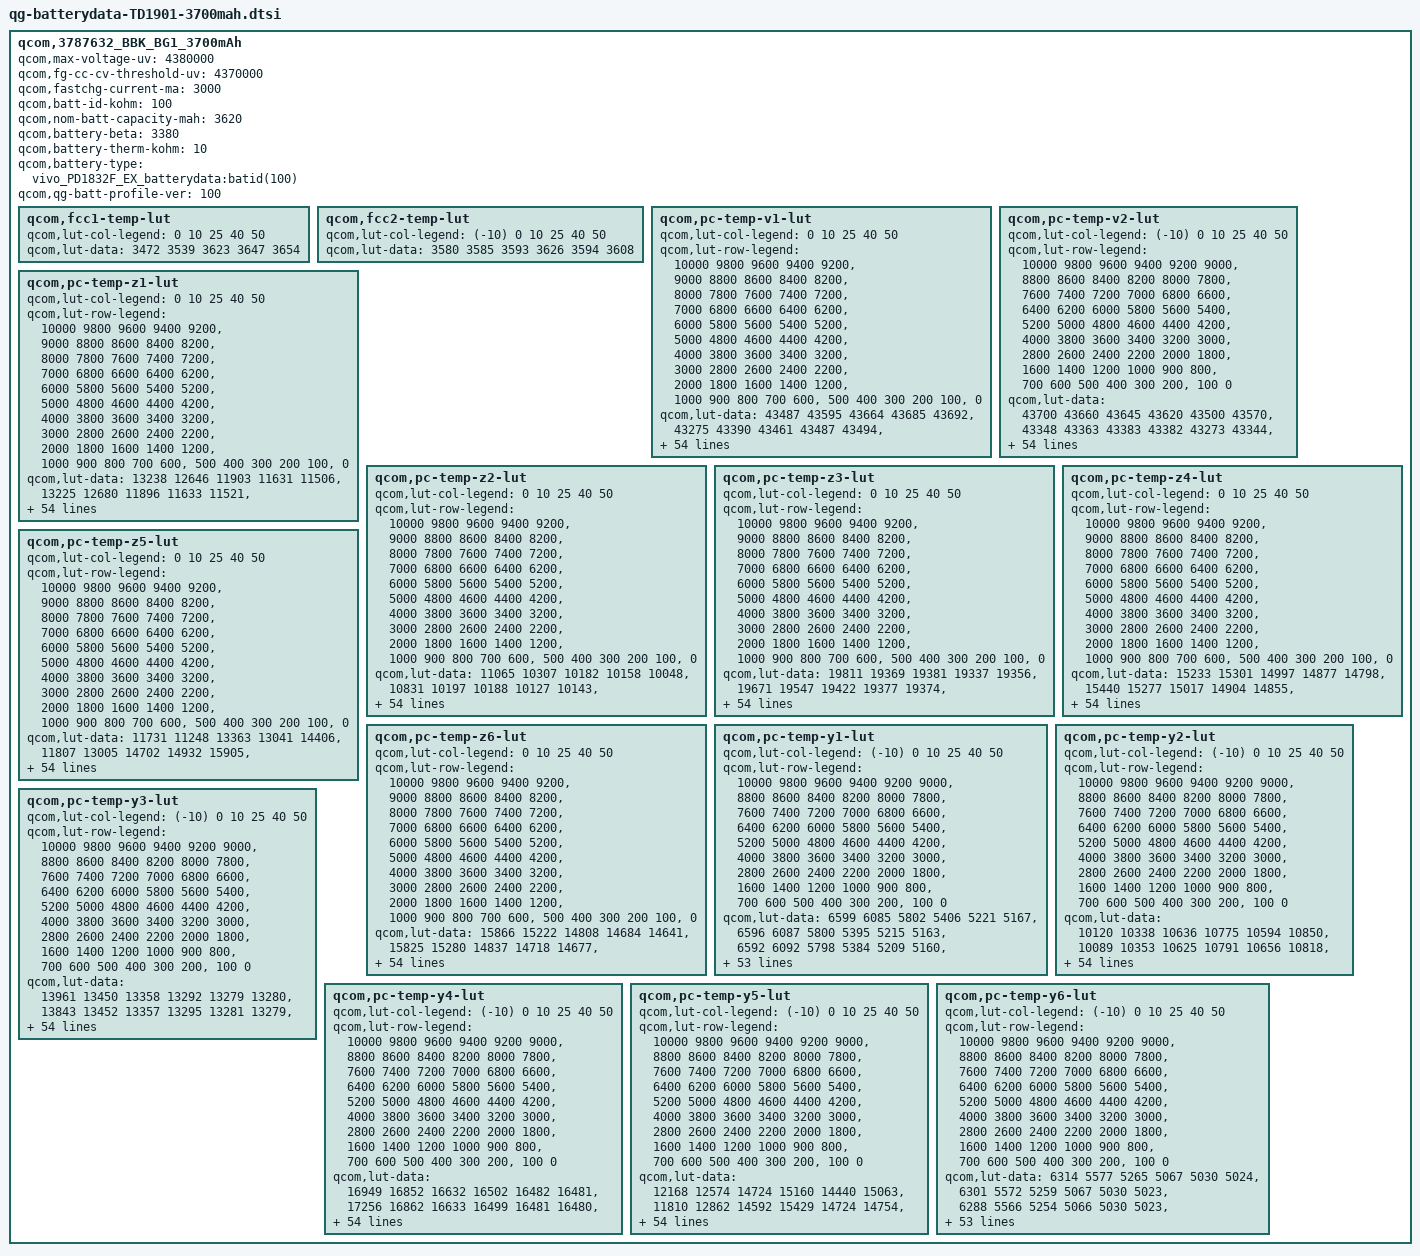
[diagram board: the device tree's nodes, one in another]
/*
 * Copyright (c) 2018, The Linux Foundation. All rights reserved.
 *
 * This program is free software; you can redistribute it and/or modify
 * it under the terms of the GNU General Public License version 2 and
 * only version 2 as published by the Free Software Foundation.
 *
 * This program is distributed in the hope that it will be useful,
 * but WITHOUT ANY WARRANTY; without even the implied warranty of
 * MERCHANTABILITY or FITNESS FOR A PARTICULAR PURPOSE.  See the
 * GNU General Public License for more details.
 */

qcom,3787632_BBK_BG1_3700mAh {
    /* 3787632_BBK_BG1_3700mAh_averaged_MasterSlave_Dec7th2018 */
    qcom,max-voltage-uv = <4380000>;
    qcom,fg-cc-cv-threshold-uv = <4370000>;
    qcom,fastchg-current-ma = <3000>;
    qcom,batt-id-kohm = <100>;
    qcom,nom-batt-capacity-mah = <3620>;/*min value*/
    qcom,battery-beta = <3380>;
    qcom,battery-therm-kohm = <10>;
    qcom,battery-type = "vivo_PD1832F_EX_batterydata:batid(100)";
    qcom,qg-batt-profile-ver = <100>;

	qcom,fcc1-temp-lut {
		qcom,lut-col-legend = <0 10 25 40 50>;
		qcom,lut-data = <3472 3539 3623 3647 3654>;
	};

	qcom,fcc2-temp-lut {
		qcom,lut-col-legend = <(-10) 0 10 25 40 50>;
		qcom,lut-data = <3580 3585 3593 3626 3594 3608>;
	};

	qcom,pc-temp-v1-lut {
		qcom,lut-col-legend = <0 10 25 40 50>;
		qcom,lut-row-legend = <10000 9800 9600 9400 9200>,
			<9000 8800 8600 8400 8200>,
			<8000 7800 7600 7400 7200>,
			<7000 6800 6600 6400 6200>,
			<6000 5800 5600 5400 5200>,
			<5000 4800 4600 4400 4200>,
			<4000 3800 3600 3400 3200>,
			<3000 2800 2600 2400 2200>,
			<2000 1800 1600 1400 1200>,
			<1000 900 800 700 600>,
			<500 400 300 200 100>,
			<0>;
		qcom,lut-data = <43487 43595 43664 43685 43692>,
			<43275 43390 43461 43487 43494>,
			<43054 43179 43248 43279 43290>,
			<42821 42960 43026 43060 43081>,
			<42580 42724 42800 42835 42865>,
			<42353 42481 42573 42611 42643>,
			<42140 42255 42344 42384 42415>,
			<41935 42044 42118 42160 42188>,
			<41729 41838 41895 41935 41963>,
			<41519 41627 41675 41713 41740>,
			<41323 41416 41460 41494 41521>,
			<41157 41218 41250 41278 41305>,
			<41005 41047 41047 41070 41094>,
			<40820 40877 40853 40875 40893>,
			<40568 40669 40660 40685 40699>,
			<40311 40422 40457 40490 40507>,
			<40124 40197 40248 40287 40316>,
			<39980 40033 40063 40098 40134>,
			<39826 39888 39917 39940 39968>,
			<39614 39710 39773 39790 39809>,
			<39382 39471 39577 39605 39622>,
			<39203 39243 39328 39367 39388>,
			<39073 39084 39114 39146 39167>,
			<38962 38955 38959 38983 39000>,
			<38860 38842 38828 38845 38859>,
			<38768 38737 38711 38723 38733>,
			<38684 38644 38607 38614 38620>,
			<38608 38559 38513 38515 38517>,
			<38539 38481 38425 38422 38423>,
			<38475 38411 38344 38336 38334>,
			<38417 38348 38275 38259 38253>,
			<38363 38291 38213 38188 38179>,
			<38316 38240 38160 38124 38110>,
			<38273 38196 38112 38068 38048>,
			<38235 38155 38069 38019 37992>,
			<38204 38117 38026 37966 37927>,
			<38173 38083 37985 37910 37850>,
			<38126 38037 37938 37848 37765>,
			<38038 37957 37867 37770 37678>,
			<37926 37849 37767 37674 37587>,
			<37812 37737 37658 37567 37482>,
			<37684 37613 37535 37440 37347>,
			<37534 37472 37398 37302 37206>,
			<37369 37307 37238 37146 37068>,
			<37249 37181 37117 37039 36963>,
			<37211 37123 37053 36975 36919>,
			<37191 37103 37033 36955 36891>,
			<37168 37087 37017 36941 36871>,
			<37126 37051 36985 36903 36822>,
			<36967 36895 36813 36691 36580>,
			<36583 36512 36436 36311 36215>,
			<36102 36035 35959 35836 35751>,
			<35489 35424 35348 35226 35134>,
			<34657 34593 34518 34395 34297>,
			<33341 33291 33222 33100 32998>,
			<30000 30000 30000 30000 30000>;
	};

	qcom,pc-temp-v2-lut {
		qcom,lut-col-legend = <(-10) 0 10 25 40 50>;
		qcom,lut-row-legend = <10000 9800 9600 9400 9200 9000>,
			<8800 8600 8400 8200 8000 7800>,
			<7600 7400 7200 7000 6800 6600>,
			<6400 6200 6000 5800 5600 5400>,
			<5200 5000 4800 4600 4400 4200>,
			<4000 3800 3600 3400 3200 3000>,
			<2800 2600 2400 2200 2000 1800>,
			<1600 1400 1200 1000 900 800>,
			<700 600 500 400 300 200>,
			<100 0>;
		qcom,lut-data = <43700 43660 43645 43620 43500 43570>,
			<43348 43363 43383 43382 43273 43344>,
			<43021 43083 43129 43148 43046 43117>,
			<42723 42820 42884 42915 42819 42891>,
			<42451 42576 42649 42687 42593 42663>,
			<42196 42340 42419 42459 42367 42437>,
			<41949 42108 42190 42230 42141 42211>,
			<41713 41880 41966 42004 41918 41987>,
			<41494 41655 41747 41781 41697 41766>,
			<41290 41427 41533 41560 41479 41548>,
			<41099 41210 41323 41343 41265 41333>,
			<40928 41027 41123 41131 41057 41121>,
			<40777 40866 40931 40923 40854 40912>,
			<40586 40684 40731 40721 40656 40711>,
			<40261 40440 40509 40521 40457 40516>,
			<39892 40174 40286 40326 40266 40327>,
			<39640 39939 40087 40136 40089 40146>,
			<39462 39724 39907 39950 39925 39973>,
			<39289 39519 39720 39763 39754 39795>,
			<39088 39320 39500 39578 39558 39611>,
			<38880 39132 39272 39390 39350 39422>,
			<38694 38959 39077 39188 39149 39220>,
			<38521 38800 38906 38972 38947 38998>,
			<38378 38655 38755 38790 38770 38808>,
			<38285 38527 38625 38656 38638 38671>,
			<38215 38411 38509 38543 38527 38558>,
			<38155 38305 38404 38438 38426 38454>,
			<38102 38203 38307 38340 38331 38358>,
			<38052 38113 38216 38249 38243 38269>,
			<38004 38039 38132 38167 38161 38182>,
			<37958 37977 38054 38091 38085 38100>,
			<37913 37925 37982 38020 38013 38024>,
			<37870 37884 37915 37955 37949 37958>,
			<37827 37848 37854 37890 37885 37889>,
			<37782 37811 37804 37822 37803 37794>,
			<37737 37775 37765 37752 37700 37673>,
			<37686 37733 37720 37678 37597 37559>,
			<37626 37683 37658 37596 37506 37459>,
			<37556 37621 37581 37510 37418 37364>,
			<37477 37540 37494 37426 37327 37270>,
			<37387 37422 37392 37342 37235 37179>,
			<37283 37287 37278 37241 37136 37080>,
			<37163 37151 37140 37098 37005 36955>,
			<37029 37014 37004 36980 36879 36843>,
			<36916 36911 36936 36915 36833 36786>,
			<36820 36831 36890 36876 36805 36747>,
			<36778 36797 36866 36857 36789 36727>,
			<36730 36754 36828 36831 36760 36706>,
			<36651 36660 36731 36748 36642 36627>,
			<36478 36420 36457 36466 36312 36328>,
			<36124 36002 36007 36018 35866 35900>,
			<35617 35450 35442 35457 35299 35383>,
			<34955 34732 34713 34732 34552 34663>,
			<34019 33703 33668 33694 33533 33760>,
			<32552 32246 32385 32504 32347 32353>,
			<29244 29005 29003 29004 29002 29001>;
	};

	qcom,pc-temp-z1-lut {
		qcom,lut-col-legend = <0 10 25 40 50>;
		qcom,lut-row-legend = <10000 9800 9600 9400 9200>,
			<9000 8800 8600 8400 8200>,
			<8000 7800 7600 7400 7200>,
			<7000 6800 6600 6400 6200>,
			<6000 5800 5600 5400 5200>,
			<5000 4800 4600 4400 4200>,
			<4000 3800 3600 3400 3200>,
			<3000 2800 2600 2400 2200>,
			<2000 1800 1600 1400 1200>,
			<1000 900 800 700 600>,
			<500 400 300 200 100>,
			<0>;
		qcom,lut-data = <13238 12646 11903 11631 11506>,
			<13225 12680 11896 11633 11521>,
			<13214 12663 11889 11633 11529>,
			<13202 12647 11879 11628 11530>,
			<13189 12632 11870 11622 11529>,
			<13184 12619 11862 11619 11527>,
			<13184 12608 11854 11616 11528>,
			<13185 12597 11847 11613 11528>,
			<13187 12589 11841 11607 11525>,
			<13197 12589 11836 11602 11520>,
			<13205 12595 11832 11601 11516>,
			<13202 12597 11829 11600 11513>,
			<13193 12587 11826 11600 11511>,
			<13180 12572 11822 11598 11515>,
			<13151 12561 11819 11596 11523>,
			<13124 12547 11818 11595 11524>,
			<13121 12540 11816 11594 11517>,
			<13130 12544 11815 11594 11510>,
			<13141 12553 11815 11594 11512>,
			<13158 12558 11815 11595 11517>,
			<13177 12559 11817 11595 11519>,
			<13182 12558 11819 11598 11523>,
			<13166 12558 11821 11601 11527>,
			<13148 12561 11827 11604 11529>,
			<13146 12564 11834 11607 11533>,
			<13146 12568 11839 11610 11533>,
			<13147 12574 11844 11613 11531>,
			<13163 12575 11848 11616 11530>,
			<13194 12577 11853 11620 11535>,
			<13204 12578 11858 11625 11549>,
			<13192 12580 11863 11629 11555>,
			<13177 12582 11868 11633 11551>,
			<13173 12585 11873 11636 11547>,
			<13172 12587 11877 11639 11550>,
			<13172 12590 11881 11643 11563>,
			<13176 12592 11884 11646 11568>,
			<13181 12594 11891 11651 11569>,
			<13187 12597 11898 11655 11571>,
			<13189 12601 11903 11658 11572>,
			<13188 12606 11908 11661 11572>,
			<13189 12610 11912 11664 11572>,
			<13194 12612 11916 11668 11579>,
			<13197 12616 11919 11671 11582>,
			<13198 12625 11922 11673 11578>,
			<13199 12623 11924 11673 11589>,
			<13196 12620 11925 11673 11582>,
			<13195 12620 11927 11673 11581>,
			<13194 12620 11930 11676 11577>,
			<13198 12626 11934 11680 11575>,
			<13208 12634 11939 11684 11590>,
			<13216 12641 11945 11687 11616>,
			<13230 12645 11950 11695 11619>,
			<13246 12653 11963 11705 11615>,
			<13267 12672 11978 11717 11617>,
			<13267 12672 11978 11717 11617>,
			<13267 12672 11978 11717 11617>;
	};

	qcom,pc-temp-z2-lut {
		qcom,lut-col-legend = <0 10 25 40 50>;
		qcom,lut-row-legend = <10000 9800 9600 9400 9200>,
			<9000 8800 8600 8400 8200>,
			<8000 7800 7600 7400 7200>,
			<7000 6800 6600 6400 6200>,
			<6000 5800 5600 5400 5200>,
			<5000 4800 4600 4400 4200>,
			<4000 3800 3600 3400 3200>,
			<3000 2800 2600 2400 2200>,
			<2000 1800 1600 1400 1200>,
			<1000 900 800 700 600>,
			<500 400 300 200 100>,
			<0>;
		qcom,lut-data = <11065 10307 10182 10158 10048>,
			<10831 10197 10188 10127 10143>,
			<10600 10417 10273 10123 10170>,
			<10325 10541 10541 10140 10122>,
			<10066 10376 10700 10155 10063>,
			<9991 10125 10833 10142 10060>,
			<10032 10082 11114 10090 10078>,
			<10085 10188 11214 10060 10091>,
			<10090 10281 11198 10070 10090>,
			<10059 10298 11170 10090 10086>,
			<10035 10303 11111 10107 10092>,
			<10075 10303 11024 10130 10116>,
			<10159 10298 10971 10140 10134>,
			<10210 10293 10942 10119 10139>,
			<10200 10306 10916 10091 10143>,
			<10169 10364 10810 10084 10146>,
			<10142 10402 10608 10081 10147>,
			<10087 10310 10524 10083 10147>,
			<10045 10150 10383 10095 10144>,
			<10021 10104 10204 10118 10137>,
			<9996 10111 10191 10144 10128>,
			<9991 10118 10254 10176 10119>,
			<10014 10109 10289 10195 10104>,
			<10036 10080 10255 10152 10051>,
			<10034 10063 10203 10061 9959>,
			<10016 10060 10178 10022 9928>,
			<10004 10057 10164 10010 9935>,
			<10005 10059 10158 10007 9946>,
			<10008 10069 10168 10018 9959>,
			<10011 10080 10185 10040 9979>,
			<10019 10087 10194 10054 9995>,
			<10029 10093 10198 10051 10004>,
			<10035 10100 10203 10049 10015>,
			<10041 10108 10215 10060 10035>,
			<10045 10115 10235 10079 10066>,
			<10050 10120 10256 10103 10088>,
			<10055 10124 10285 10149 10116>,
			<10061 10129 10317 10192 10142>,
			<10073 10152 10349 10210 10152>,
			<10083 10180 10383 10233 10165>,
			<10081 10185 10393 10244 10167>,
			<10070 10180 10368 10247 10163>,
			<10069 10179 10354 10248 10156>,
			<10074 10190 10367 10235 10098>,
			<10120 10193 10351 10186 10093>,
			<11410 10209 10311 10188 10160>,
			<10002 10209 10296 10153 10094>,
			<10006 10208 10300 10225 10153>,
			<10186 10233 10336 10219 10197>,
			<10321 10287 10348 10071 9959>,
			<10106 10281 10227 10006 9925>,
			<9993 10254 10184 9985 9892>,
			<9959 10211 10159 9975 9879>,
			<9738 10153 10136 9922 9847>,
			<9738 10153 10136 9922 9847>,
			<9738 10153 10136 9922 9847>;
	};

	qcom,pc-temp-z3-lut {
		qcom,lut-col-legend = <0 10 25 40 50>;
		qcom,lut-row-legend = <10000 9800 9600 9400 9200>,
			<9000 8800 8600 8400 8200>,
			<8000 7800 7600 7400 7200>,
			<7000 6800 6600 6400 6200>,
			<6000 5800 5600 5400 5200>,
			<5000 4800 4600 4400 4200>,
			<4000 3800 3600 3400 3200>,
			<3000 2800 2600 2400 2200>,
			<2000 1800 1600 1400 1200>,
			<1000 900 800 700 600>,
			<500 400 300 200 100>,
			<0>;
		qcom,lut-data = <19811 19369 19381 19337 19356>,
			<19671 19547 19422 19377 19374>,
			<19618 19564 19440 19395 19381>,
			<19685 19581 19449 19400 19377>,
			<19812 19615 19453 19402 19373>,
			<19857 19649 19452 19399 19373>,
			<19828 19655 19452 19388 19375>,
			<19790 19649 19452 19382 19375>,
			<19782 19642 19454 19381 19375>,
			<19794 19626 19456 19381 19373>,
			<19800 19596 19452 19381 19372>,
			<19760 19582 19442 19380 19371>,
			<19692 19583 19438 19379 19370>,
			<19670 19584 19441 19372 19365>,
			<19719 19589 19444 19365 19359>,
			<19778 19602 19439 19364 19356>,
			<19788 19610 19425 19367 19355>,
			<19774 19604 19419 19369 19354>,
			<19765 19592 19409 19366 19352>,
			<19787 19591 19394 19362 19351>,
			<19822 19611 19402 19366 19354>,
			<19834 19633 19439 19395 19382>,
			<19826 19644 19465 19417 19405>,
			<19817 19652 19470 19416 19404>,
			<19816 19656 19473 19412 19399>,
			<19823 19655 19472 19409 19396>,
			<19827 19650 19467 19407 19393>,
			<19823 19646 19462 19404 19390>,
			<19813 19638 19462 19403 19388>,
			<19805 19630 19461 19401 19385>,
			<19800 19623 19459 19400 19382>,
			<19794 19616 19450 19396 19375>,
			<19788 19610 19441 19393 19368>,
			<19782 19604 19435 19389 19365>,
			<19777 19600 19431 19385 19361>,
			<19771 19598 19427 19382 19360>,
			<19764 19597 19423 19380 19365>,
			<19761 19594 19419 19378 19371>,
			<19757 19588 19415 19379 19372>,
			<19751 19579 19412 19381 19373>,
			<19745 19570 19409 19384 19375>,
			<19736 19560 19408 19387 19380>,
			<19733 19555 19407 19391 19382>,
			<19731 19554 19413 19396 19374>,
			<19677 19550 19406 19385 19380>,
			<19326 19517 19382 19372 19339>,
			<19265 19515 19379 19363 19342>,
			<19265 19512 19382 19346 19337>,
			<19263 19504 19375 19342 19337>,
			<19262 19497 19392 19387 19375>,
			<19263 19492 19388 19394 19371>,
			<19264 19496 19408 19392 19375>,
			<19264 19505 19413 19387 19365>,
			<19267 19507 19414 19383 19370>,
			<19267 19507 19414 19383 19370>,
			<19267 19507 19414 19383 19370>;
	};

	qcom,pc-temp-z4-lut {
		qcom,lut-col-legend = <0 10 25 40 50>;
		qcom,lut-row-legend = <10000 9800 9600 9400 9200>,
			<9000 8800 8600 8400 8200>,
			<8000 7800 7600 7400 7200>,
			<7000 6800 6600 6400 6200>,
			<6000 5800 5600 5400 5200>,
			<5000 4800 4600 4400 4200>,
			<4000 3800 3600 3400 3200>,
			<3000 2800 2600 2400 2200>,
			<2000 1800 1600 1400 1200>,
			<1000 900 800 700 600>,
			<500 400 300 200 100>,
			<0>;
		qcom,lut-data = <15233 15301 14997 14877 14798>,
			<15440 15277 15017 14904 14855>,
			<15519 15200 15001 14909 14872>,
			<15438 15118 14934 14881 14854>,
			<15269 15048 14878 14847 14827>,
			<15157 14984 14855 14837 14816>,
			<15098 14935 14836 14833 14810>,
			<15058 14888 14820 14829 14806>,
			<15033 14861 14803 14822 14802>,
			<15006 14865 14790 14814 14798>,
			<14992 14880 14784 14806 14792>,
			<15002 14888 14779 14798 14784>,
			<15023 14871 14773 14791 14776>,
			<15032 14852 14763 14785 14770>,
			<15032 14850 14754 14778 14765>,
			<15031 14857 14753 14772 14760>,
			<15017 14862 14758 14765 14754>,
			<14971 14850 14758 14757 14747>,
			<14942 14829 14752 14747 14738>,
			<15027 14838 14750 14737 14729>,
			<15182 14976 14786 14745 14734>,
			<15232 15106 14884 14810 14789>,
			<15217 15096 14937 14861 14836>,
			<15190 15037 14917 14856 14832>,
			<15155 14987 14885 14841 14818>,
			<15100 14958 14866 14828 14806>,
			<15055 14936 14852 14817 14797>,
			<15032 14920 14840 14806 14788>,
			<15015 14908 14827 14796 14782>,
			<15004 14899 14816 14787 14778>,
			<14995 14893 14809 14779 14772>,
			<14990 14889 14804 14773 14764>,
			<14986 14884 14800 14767 14754>,
			<14984 14880 14794 14762 14746>,
			<14981 14875 14790 14757 14738>,
			<14975 14871 14788 14756 14736>,
			<14968 14867 14790 14766 14758>,
			<14966 14865 14794 14777 14784>,
			<14973 14872 14799 14778 14783>,
			<14981 14883 14807 14777 14769>,
			<14979 14883 14809 14774 14760>,
			<14968 14872 14798 14766 14774>,
			<14960 14868 14791 14761 14784>,
			<14953 14868 14793 14769 14778>,
			<14913 14831 14784 14755 14752>,
			<15225 14821 14776 14730 14724>,
			<15272 14798 14753 14719 14705>,
			<15256 14781 14722 14704 14681>,
			<15254 14781 14715 14691 14668>,
			<15268 14809 14730 14698 14724>,
			<15285 14824 14745 14700 14746>,
			<15290 14820 14726 14704 14716>,
			<15296 14813 14723 14707 14710>,
			<15303 14815 14722 14710 14701>,
			<15303 14815 14722 14710 14701>,
			<15303 14815 14722 14710 14701>;
	};

	qcom,pc-temp-z5-lut {
		qcom,lut-col-legend = <0 10 25 40 50>;
		qcom,lut-row-legend = <10000 9800 9600 9400 9200>,
			<9000 8800 8600 8400 8200>,
			<8000 7800 7600 7400 7200>,
			<7000 6800 6600 6400 6200>,
			<6000 5800 5600 5400 5200>,
			<5000 4800 4600 4400 4200>,
			<4000 3800 3600 3400 3200>,
			<3000 2800 2600 2400 2200>,
			<2000 1800 1600 1400 1200>,
			<1000 900 800 700 600>,
			<500 400 300 200 100>,
			<0>;
		qcom,lut-data = <11731 11248 13363 13041 14406>,
			<11807 13005 14702 14932 15905>,
			<12012 13130 15408 16073 16590>,
			<13187 13345 15886 16732 16393>,
			<15266 15001 16201 17119 16144>,
			<16305 17293 16350 16972 16243>,
			<16228 17796 16500 16292 16567>,
			<15863 17252 16729 15919 16756>,
			<15888 16567 17326 16051 16813>,
			<16626 15980 17799 16285 16874>,
			<17164 15392 17610 16456 16989>,
			<16173 15185 17106 16659 17241>,
			<14335 15442 16944 16748 17385>,
			<13725 15849 17339 16375 17151>,
			<15199 16147 17822 15831 16777>,
			<17109 16380 17797 15792 16711>,
			<17651 16698 17410 16198 16842>,
			<17603 17608 17337 16697 17038>,
			<17787 18835 17202 17253 17437>,
			<19442 19154 16867 17778 17961>,
			<21926 18704 16700 17826 18068>,
			<22552 18115 16525 17392 17750>,
			<19923 17681 16437 16876 17306>,
			<17134 17279 16462 16387 16804>,
			<16956 17142 16527 15881 16267>,
			<17691 17726 16657 15767 16154>,
			<18396 18574 16982 16057 16521>,
			<18869 19078 17450 16476 16912>,
			<19402 19618 18399 16937 17165>,
			<19888 20122 19518 17524 17530>,
			<20479 20522 19791 18044 17671>,
			<20959 20873 19784 18452 17624>,
			<21106 21092 19784 18876 17572>,
			<21182 21301 20105 19556 17868>,
			<21216 21452 20749 20419 18700>,
			<21037 21513 20936 20703 19150>,
			<20768 21635 20619 20040 19401>,
			<20713 21668 20106 19264 19672>,
			<20742 21195 19412 19139 19921>,
			<20656 20314 18472 19198 20431>,
			<20148 19431 17922 19359 20986>,
			<19217 18421 17705 20138 21787>,
			<19033 17829 17558 20645 22172>,
			<19132 17532 17460 20493 19479>,
			<17808 18469 16839 18427 20444>,
			<11997 16606 15253 16620 15240>,
			<10851 16919 15615 16373 15297>,
			<10848 17042 16911 15623 16303>,
			<10849 16619 16998 16630 18507>,
			<10847 15355 16304 20248 20239>,
			<10822 14640 15157 20114 18890>,
			<10801 14710 16902 18682 18621>,
			<10760 14861 17081 17299 15276>,
			<10721 14734 16365 15445 14972>,
			<10721 14734 16365 15445 14972>,
			<10721 14734 16365 15445 14972>;
	};

	qcom,pc-temp-z6-lut {
		qcom,lut-col-legend = <0 10 25 40 50>;
		qcom,lut-row-legend = <10000 9800 9600 9400 9200>,
			<9000 8800 8600 8400 8200>,
			<8000 7800 7600 7400 7200>,
			<7000 6800 6600 6400 6200>,
			<6000 5800 5600 5400 5200>,
			<5000 4800 4600 4400 4200>,
			<4000 3800 3600 3400 3200>,
			<3000 2800 2600 2400 2200>,
			<2000 1800 1600 1400 1200>,
			<1000 900 800 700 600>,
			<500 400 300 200 100>,
			<0>;
		qcom,lut-data = <15866 15222 14808 14684 14641>,
			<15825 15280 14837 14718 14677>,
			<15781 15238 14836 14729 14690>,
			<15733 15197 14812 14719 14681>,
			<15682 15170 14789 14706 14667>,
			<15630 15146 14777 14697 14662>,
			<15566 15121 14769 14689 14660>,
			<15511 15095 14761 14684 14658>,
			<15489 15073 14754 14679 14656>,
			<15478 15060 14747 14675 14652>,
			<15467 15051 14740 14672 14648>,
			<15441 15042 14732 14668 14643>,
			<15409 15031 14727 14663 14639>,
			<15400 15022 14723 14657 14635>,
			<15414 15022 14720 14650 14630>,
			<15431 15025 14716 14646 14626>,
			<15428 15027 14711 14644 14622>,
			<15403 15018 14706 14642 14617>,
			<15385 15003 14697 14636 14613>,
			<15432 15006 14690 14630 14609>,
			<15519 15078 14707 14635 14613>,
			<15547 15146 14772 14681 14653>,
			<15539 15145 14808 14716 14687>,
			<15526 15126 14803 14714 14686>,
			<15513 15110 14793 14706 14678>,
			<15496 15098 14785 14699 14671>,
			<15481 15088 14777 14693 14665>,
			<15469 15079 14770 14687 14660>,
			<15459 15072 14765 14683 14657>,
			<15454 15066 14762 14678 14655>,
			<15451 15061 14757 14674 14651>,
			<15449 15058 14751 14670 14643>,
			<15449 15055 14745 14666 14634>,
			<15449 15052 14740 14661 14629>,
			<15450 15051 14736 14657 14625>,
			<15449 15051 14735 14656 14624>,
			<15450 15051 14735 14659 14636>,
			<15451 15052 14735 14663 14650>,
			<15460 15055 14736 14665 14650>,
			<15468 15059 14739 14666 14644>,
			<15468 15058 14739 14667 14641>,
			<15467 15052 14735 14666 14651>,
			<15469 15050 14732 14665 14658>,
			<15475 15054 14737 14672 14650>,
			<15446 15043 14730 14661 14643>,
			<15412 15022 14714 14643 14611>,
			<15402 15012 14704 14634 14603>,
			<15400 15005 14691 14618 14589>,
			<15403 15005 14686 14611 14582>,
			<15420 15018 14703 14640 14631>,
			<15436 15026 14709 14646 14643>,
			<15448 15032 14714 14649 14634>,
			<15465 15040 14718 14651 14627>,
			<15490 15052 14722 14653 14629>,
			<15490 15052 14722 14653 14629>,
			<15490 15052 14722 14653 14629>;
	};

	qcom,pc-temp-y1-lut {
		qcom,lut-col-legend = <(-10) 0 10 25 40 50>;
		qcom,lut-row-legend = <10000 9800 9600 9400 9200 9000>,
			<8800 8600 8400 8200 8000 7800>,
			<7600 7400 7200 7000 6800 6600>,
			<6400 6200 6000 5800 5600 5400>,
			<5200 5000 4800 4600 4400 4200>,
			<4000 3800 3600 3400 3200 3000>,
			<2800 2600 2400 2200 2000 1800>,
			<1600 1400 1200 1000 900 800>,
			<700 600 500 400 300 200>,
			<100 0>;
		qcom,lut-data = <6599 6085 5802 5406 5221 5167>,
			<6596 6087 5800 5395 5215 5163>,
			<6592 6092 5798 5384 5209 5160>,
			<6589 6097 5795 5374 5203 5156>,
			<6585 6101 5792 5364 5198 5152>,
			<6583 6103 5788 5356 5194 5147>,
			<6578 6103 5781 5348 5190 5142>,
			<6572 6103 5771 5342 5188 5137>,
			<6569 6101 5767 5335 5185 5134>,
			<6569 6092 5765 5329 5183 5132>,
			<6570 6081 5764 5324 5181 5132>,
			<6572 6077 5761 5318 5178 5134>,
			<6580 6074 5755 5313 5175 5139>,
			<6584 6073 5750 5310 5172 5142>,
			<6583 6073 5744 5308 5170 5141>,
			<6581 6075 5741 5306 5168 5140>,
			<6582 6076 5741 5305 5168 5140>,
			<6584 6079 5743 5304 5169 5141>,
			<6585 6082 5745 5303 5170 5141>,
			<6585 6081 5742 5303 5170 5142>,
			<6584 6081 5738 5302 5170 5142>,
			<6584 6081 5737 5303 5170 5142>,
			<6584 6081 5738 5305 5171 5141>,
			<6582 6081 5740 5307 5172 5140>,
			<6574 6080 5742 5308 5173 5139>,
			<6555 6079 5744 5310 5173 5139>,
			<6547 6078 5745 5312 5174 5140>,
			<6555 6080 5746 5315 5176 5142>,
			<6565 6082 5747 5318 5179 5146>,
			<6567 6082 5748 5322 5182 5150>,
			<6568 6081 5749 5327 5185 5155>,
			<6569 6080 5751 5331 5188 5159>,
			<6564 6081 5753 5336 5192 5163>,
			<6556 6082 5756 5340 5195 5166>,
			<6552 6082 5759 5343 5196 5166>,
			<6549 6082 5761 5348 5197 5165>,
			<6546 6081 5763 5350 5198 5164>,
			<6538 6081 5764 5352 5199 5161>,
			<6526 6081 5767 5353 5201 5158>,
			<6522 6079 5768 5355 5204 5159>,
			<6526 6073 5770 5357 5207 5163>,
			<6529 6068 5773 5360 5210 5169>,
			<6527 6072 5779 5365 5212 5179>,
			<6523 6080 5787 5370 5214 5186>,
			<6512 6073 5793 5375 5217 5177>,
			<6501 6066 5802 5380 5218 5177>,
			<6506 6071 5810 5381 5218 5185>,
			<6516 6073 5806 5380 5218 5175>,
			<6518 6074 5804 5381 5218 5181>,
			<6506 6070 5796 5380 5221 5184>,
			<6509 6076 5807 5386 5225 5181>,
			<6533 6069 5817 5391 5232 5190>,
			<6524 6081 5831 5403 5240 5198>,
			<6560 6115 5848 5417 5249 5200>,
			<6560 6115 5848 5417 5249 5200>,
			<6560 6115 5848 5417 5249 5200>;
	};

	qcom,pc-temp-y2-lut {
		qcom,lut-col-legend = <(-10) 0 10 25 40 50>;
		qcom,lut-row-legend = <10000 9800 9600 9400 9200 9000>,
			<8800 8600 8400 8200 8000 7800>,
			<7600 7400 7200 7000 6800 6600>,
			<6400 6200 6000 5800 5600 5400>,
			<5200 5000 4800 4600 4400 4200>,
			<4000 3800 3600 3400 3200 3000>,
			<2800 2600 2400 2200 2000 1800>,
			<1600 1400 1200 1000 900 800>,
			<700 600 500 400 300 200>,
			<100 0>;
		qcom,lut-data = <10120 10338 10636 10775 10594 10850>,
			<10089 10353 10625 10791 10656 10818>,
			<10076 10368 10614 10797 10700 10783>,
			<10077 10381 10604 10796 10729 10749>,
			<10088 10393 10596 10788 10745 10723>,
			<10105 10403 10593 10778 10751 10707>,
			<10131 10411 10594 10758 10736 10705>,
			<10172 10418 10597 10731 10702 10708>,
			<10218 10423 10599 10718 10684 10703>,
			<10279 10426 10599 10713 10680 10685>,
			<10337 10430 10600 10716 10677 10667>,
			<10365 10455 10602 10746 10668 10663>,
			<10382 10524 10608 10798 10655 10666>,
			<10403 10583 10617 10816 10648 10668>,
			<10436 10626 10661 10807 10649 10669>,
			<10476 10657 10721 10797 10656 10669>,
			<10528 10660 10761 10823 10681 10663>,
			<10603 10656 10795 10911 10760 10649>,
			<10647 10654 10810 10968 10839 10643>,
			<10390 10662 10802 10991 10905 10700>,
			<9894 10684 10788 11005 10960 10784>,
			<9716 10706 10789 10988 10965 10805>,
			<9690 10731 10819 10923 10923 10799>,
			<9677 10758 10854 10887 10881 10792>,
			<9673 10788 10875 10918 10876 10813>,
			<9671 10818 10894 10973 10891 10859>,
			<9669 10839 10910 11006 10901 10872>,
			<9668 10851 10925 11029 10898 10852>,
			<9666 10861 10940 11049 10894 10834>,
			<9664 10875 10953 11067 10913 10845>,
			<9663 10891 10967 11083 10967 10874>,
			<9661 10898 10978 11098 11003 10904>,
			<9660 10875 10990 11113 11009 10939>,
			<9659 10831 10999 11122 11009 10966>,
			<9658 10795 10996 11121 11002 10975>,
			<9657 10764 10974 11115 10957 10979>,
			<9656 10731 10951 11114 10921 10976>,
			<9656 10701 10940 11102 10931 10924>,
			<9655 10666 10930 11086 10956 10853>,
			<9655 10586 10915 11083 10958 10833>,
			<9654 10315 10883 11084 10920 10826>,
			<9654 10019 10840 11080 10882 10824>,
			<9653 9847 10786 11050 10876 10837>,
			<9653 9720 10716 11033 10871 10853>,
			<9653 9687 10629 10986 10786 10734>,
			<9652 9677 10557 10905 10698 10654>,
			<9652 9672 10538 10879 10697 10645>,
			<9652 9669 10531 10871 10719 10650>,
			<9652 9667 10526 10872 10729 10622>,
			<9652 9665 10467 10860 10688 10603>,
			<9652 9661 10414 10837 10641 10585>,
			<9651 9658 10344 10775 10582 10531>,
			<9650 9656 10290 10679 10526 10471>,
			<9649 9654 10216 10621 10402 10372>,
			<9649 9654 10216 10621 10402 10372>,
			<9649 9654 10216 10621 10402 10372>;
	};

	qcom,pc-temp-y3-lut {
		qcom,lut-col-legend = <(-10) 0 10 25 40 50>;
		qcom,lut-row-legend = <10000 9800 9600 9400 9200 9000>,
			<8800 8600 8400 8200 8000 7800>,
			<7600 7400 7200 7000 6800 6600>,
			<6400 6200 6000 5800 5600 5400>,
			<5200 5000 4800 4600 4400 4200>,
			<4000 3800 3600 3400 3200 3000>,
			<2800 2600 2400 2200 2000 1800>,
			<1600 1400 1200 1000 900 800>,
			<700 600 500 400 300 200>,
			<100 0>;
		qcom,lut-data = <13961 13450 13358 13292 13279 13280>,
			<13843 13452 13357 13295 13281 13279>,
			<13769 13455 13356 13297 13282 13279>,
			<13730 13458 13355 13298 13284 13279>,
			<13714 13461 13355 13298 13284 13279>,
			<13711 13462 13355 13298 13285 13279>,
			<13735 13463 13355 13298 13284 13281>,
			<13788 13463 13355 13297 13284 13282>,
			<13800 13463 13356 13296 13284 13283>,
			<13667 13459 13362 13297 13284 13283>,
			<13525 13455 13367 13297 13284 13283>,
			<13531 13455 13367 13298 13286 13283>,
			<13594 13456 13366 13299 13290 13283>,
			<13628 13456 13365 13301 13292 13284>,
			<13607 13448 13365 13302 13292 13287>,
			<13572 13435 13365 13304 13292 13291>,
			<13543 13427 13365 13306 13292 13291>,
			<13517 13423 13363 13308 13296 13290>,
			<13494 13417 13361 13309 13298 13289>,
			<13479 13410 13356 13309 13298 13290>,
			<13465 13401 13348 13307 13296 13292>,
			<13444 13393 13342 13304 13293 13291>,
			<13402 13387 13337 13296 13285 13283>,
			<13370 13380 13333 13292 13279 13278>,
			<13371 13373 13331 13293 13280 13278>,
			<13383 13367 13330 13294 13281 13279>,
			<13398 13362 13329 13294 13282 13280>,
			<13419 13359 13328 13293 13284 13282>,
			<13445 13356 13327 13292 13284 13284>,
			<13469 13352 13327 13292 13284 13283>,
			<13494 13346 13325 13293 13284 13282>,
			<13524 13343 13324 13293 13284 13281>,
			<13560 13346 13324 13294 13284 13281>,
			<13604 13353 13323 13294 13285 13281>,
			<13655 13358 13325 13293 13285 13281>,
			<13714 13362 13327 13292 13283 13278>,
			<13781 13367 13329 13291 13282 13277>,
			<13855 13372 13327 13288 13282 13278>,
			<13938 13376 13324 13285 13281 13280>,
			<14033 13377 13323 13287 13282 13281>,
			<14145 13364 13323 13291 13283 13281>,
			<14271 13351 13324 13292 13283 13281>,
			<14411 13360 13324 13289 13282 13280>,
			<14569 13392 13325 13286 13281 13280>,
			<14746 13426 13332 13292 13284 13284>,
			<14933 13477 13349 13295 13291 13288>,
			<15035 13521 13359 13297 13296 13288>,
			<15089 13542 13363 13307 13299 13291>,
			<15059 13541 13366 13310 13297 13290>,
			<15162 13579 13365 13305 13290 13292>,
			<15313 13651 13371 13302 13295 13290>,
			<15528 13767 13383 13305 13297 13292>,
			<16096 13946 13407 13312 13300 13296>,
			<17347 14305 13463 13320 13306 13298>,
			<17347 14305 13463 13320 13306 13298>,
			<17347 14305 13463 13320 13306 13298>;
	};

	qcom,pc-temp-y4-lut {
		qcom,lut-col-legend = <(-10) 0 10 25 40 50>;
		qcom,lut-row-legend = <10000 9800 9600 9400 9200 9000>,
			<8800 8600 8400 8200 8000 7800>,
			<7600 7400 7200 7000 6800 6600>,
			<6400 6200 6000 5800 5600 5400>,
			<5200 5000 4800 4600 4400 4200>,
			<4000 3800 3600 3400 3200 3000>,
			<2800 2600 2400 2200 2000 1800>,
			<1600 1400 1200 1000 900 800>,
			<700 600 500 400 300 200>,
			<100 0>;
		qcom,lut-data = <16949 16852 16632 16502 16482 16481>,
			<17256 16862 16633 16499 16481 16480>,
			<17446 16876 16635 16498 16480 16479>,
			<17547 16891 16638 16498 16480 16479>,
			<17587 16902 16640 16499 16480 16479>,
			<17594 16908 16642 16500 16481 16478>,
			<17531 16907 16644 16504 16483 16479>,
			<17387 16905 16645 16511 16488 16480>,
			<17354 16903 16647 16517 16492 16482>,
			<17706 16900 16650 16524 16497 16487>,
			<18080 16898 16655 16531 16501 16493>,
			<18103 16944 16665 16537 16503 16496>,
			<18040 17090 16685 16543 16505 16498>,
			<17946 17165 16711 16552 16509 16500>,
			<17687 17151 16746 16564 16516 16502>,
			<17387 17123 16787 16580 16528 16506>,
			<17307 17084 16824 16600 16541 16513>,
			<17292 17011 16863 16626 16557 16528>,
			<17274 16936 16881 16642 16569 16542>,
			<17216 16871 16815 16653 16575 16556>,
			<17124 16810 16693 16659 16577 16568>,
			<17047 16766 16627 16638 16567 16562>,
			<16972 16730 16589 16556 16525 16519>,
			<16923 16705 16569 16504 16492 16488>,
			<16914 16693 16566 16497 16489 16486>,
			<16909 16686 16564 16494 16487 16485>,
			<16907 16676 16564 16495 16487 16485>,
			<16905 16650 16566 16501 16490 16490>,
			<16902 16626 16570 16508 16495 16495>,
			<16905 16625 16574 16517 16501 16498>,
			<16915 16630 16578 16526 16509 16500>,
			<16926 16637 16580 16534 16518 16504>,
			<16935 16645 16577 16543 16529 16513>,
			<16944 16654 16572 16549 16538 16520>,
			<16952 16667 16574 16545 16534 16513>,
			<16959 16686 16586 16535 16511 16488>,
			<16964 16703 16593 16523 16491 16475>,
			<16968 16713 16586 16508 16484 16476>,
			<16971 16720 16574 16497 16479 16477>,
			<16975 16730 16571 16497 16478 16476>,
			<16980 16743 16574 16498 16481 16467>,
			<16984 16757 16580 16499 16483 16460>,
			<16987 16771 16586 16499 16477 16455>,
			<16988 16789 16597 16500 16466 16453>,
			<17011 16837 16618 16502 16474 16466>,
			<17102 16948 16671 16524 16513 16502>,
			<17207 17049 16729 16548 16571 16537>,
			<17279 17096 16752 16574 16607 16608>,
			<17259 17056 16747 16592 16574 16595>,
			<17270 17030 16718 16522 16494 16465>,
			<17219 17019 16711 16514 16494 16488>,
			<17216 17071 16762 16532 16505 16506>,
			<17441 17179 16844 16578 16528 16478>,
			<18270 17363 17000 16695 16677 16620>,
			<18270 17363 17000 16695 16677 16620>,
			<18270 17363 17000 16695 16677 16620>;
	};

	qcom,pc-temp-y5-lut {
		qcom,lut-col-legend = <(-10) 0 10 25 40 50>;
		qcom,lut-row-legend = <10000 9800 9600 9400 9200 9000>,
			<8800 8600 8400 8200 8000 7800>,
			<7600 7400 7200 7000 6800 6600>,
			<6400 6200 6000 5800 5600 5400>,
			<5200 5000 4800 4600 4400 4200>,
			<4000 3800 3600 3400 3200 3000>,
			<2800 2600 2400 2200 2000 1800>,
			<1600 1400 1200 1000 900 800>,
			<700 600 500 400 300 200>,
			<100 0>;
		qcom,lut-data = <12168 12574 14724 15160 14440 15063>,
			<11810 12862 14592 15429 14724 14754>,
			<11642 13296 14389 15497 14856 14568>,
			<11629 13760 14165 15405 14865 14475>,
			<11736 14143 13971 15198 14782 14445>,
			<11928 14330 13859 14917 14638 14449>,
			<12557 14318 13773 14455 14259 14528>,
			<13636 14268 13641 13844 13614 14679>,
			<13940 14183 13620 13435 13208 14698>,
			<12578 13829 13907 13147 12962 14301>,
			<11125 13381 14196 12961 12820 13789>,
			<11780 13064 13996 12886 13024 13430>,
			<14408 12782 13334 12835 13647 13109>,
			<15795 12680 13016 12788 13932 13015>,
			<15171 13256 13071 12719 13520 13389>,
			<14313 14220 13198 12667 13003 13826>,
			<14220 14929 13573 12738 12981 13748>,
			<14571 15558 14688 13062 13297 13266>,
			<14818 15936 15687 13568 13764 13001>,
			<14588 16077 16277 15094 14794 13726>,
			<13984 16176 16713 16682 16032 14780>,
			<13237 16174 16741 16763 16164 14904>,
			<11978 15908 16216 16254 15050 14422>,
			<10991 15542 15662 15962 14130 14072>,
			<10858 15193 15430 16307 14299 14287>,
			<10830 14826 15255 16797 14781 14799>,
			<10833 14706 15176 16769 15106 15340>,
			<10905 14904 15204 16066 15310 16105>,
			<10982 15126 15263 15458 15433 16599>,
			<10971 14896 15311 15388 15277 16120>,
			<10919 13984 15368 15514 14824 15019>,
			<10888 13472 15370 15691 14629 14602>,
			<10922 13766 15541 16133 14960 14744>,
			<11001 14328 15865 16455 15451 14918>,
			<11111 14799 16218 16458 15635 14783>,
			<11312 15235 16815 16390 15656 14377>,
			<11475 15608 17138 16179 15662 14221>,
			<11531 15924 16646 15239 15586 15402>,
			<11567 16181 15686 14413 15319 16885>,
			<11569 16048 15052 14762 15180 17012>,
			<11517 14066 14620 15703 15142 16599>,
			<11430 12073 14241 16043 15094 16335>,
			<11309 11719 13797 15131 15066 16328>,
			<11157 11594 13449 14269 15075 16326>,
			<11147 11556 13642 14725 14889 16331>,
			<11190 11537 13992 14068 14878 15722>,
			<11268 11497 13931 13862 14779 14034>,
			<11384 11485 13915 15381 14811 13860>,
			<11492 11555 14545 16078 14976 13256>,
			<11515 11660 14589 16599 14899 21875>,
			<11420 11709 14719 16123 17802 17061>,
			<11338 11605 14613 16162 17450 15106>,
			<10899 11470 14835 17269 17455 18893>,
			<10019 11357 15333 17298 17869 17428>,
			<10019 11357 15333 17298 17869 17428>,
			<10019 11357 15333 17298 17869 17428>;
	};

	qcom,pc-temp-y6-lut {
		qcom,lut-col-legend = <(-10) 0 10 25 40 50>;
		qcom,lut-row-legend = <10000 9800 9600 9400 9200 9000>,
			<8800 8600 8400 8200 8000 7800>,
			<7600 7400 7200 7000 6800 6600>,
			<6400 6200 6000 5800 5600 5400>,
			<5200 5000 4800 4600 4400 4200>,
			<4000 3800 3600 3400 3200 3000>,
			<2800 2600 2400 2200 2000 1800>,
			<1600 1400 1200 1000 900 800>,
			<700 600 500 400 300 200>,
			<100 0>;
		qcom,lut-data = <6314 5577 5265 5067 5030 5024>,
			<6301 5572 5259 5067 5030 5023>,
			<6288 5566 5254 5066 5030 5023>,
			<6275 5559 5248 5065 5031 5022>,
			<6262 5552 5243 5064 5031 5022>,
			<6249 5545 5239 5064 5031 5022>,
			<6233 5536 5235 5064 5032 5023>,
			<6218 5527 5232 5064 5032 5024>,
			<6213 5518 5231 5065 5033 5025>,
			<6216 5507 5232 5066 5034 5026>,
			<6223 5499 5233 5068 5035 5028>,
			<6236 5509 5235 5070 5037 5029>,
			<6259 5544 5238 5072 5040 5030>,
			<6270 5561 5242 5075 5043 5032>,
			<6199 5551 5250 5079 5045 5034>,
			<6095 5532 5260 5085 5047 5038>,
			<6062 5513 5269 5092 5052 5041>,
			<6054 5491 5278 5100 5059 5044>,
			<6045 5467 5282 5105 5064 5047>,
			<6020 5444 5260 5107 5065 5052>,
			<5983 5421 5218 5108 5064 5056>,
			<5958 5405 5195 5100 5059 5053>,
			<5939 5391 5180 5070 5041 5035>,
			<5928 5382 5172 5053 5027 5022>,
			<5937 5377 5171 5052 5027 5022>,
			<5966 5374 5170 5052 5027 5022>,
			<5998 5372 5170 5052 5028 5022>,
			<6029 5370 5171 5053 5029 5025>,
			<6062 5369 5173 5055 5032 5027>,
			<6096 5370 5175 5058 5034 5028>,
			<6132 5375 5177 5061 5036 5029>,
			<6171 5384 5179 5064 5038 5030>,
			<6213 5397 5179 5068 5042 5033>,
			<6259 5416 5180 5070 5045 5035>,
			<6309 5436 5184 5069 5044 5033>,
			<6365 5457 5192 5066 5037 5024>,
			<6426 5480 5197 5062 5031 5019>,
			<6489 5504 5196 5056 5029 5020>,
			<6558 5530 5195 5052 5027 5022>,
			<6636 5556 5195 5053 5027 5021>,
			<6725 5577 5200 5057 5029 5020>,
			<6824 5603 5208 5058 5031 5018>,
			<6934 5645 5216 5057 5028 5018>,
			<7058 5707 5228 5056 5025 5018>,
			<7204 5789 5251 5061 5029 5023>,
			<7376 5904 5294 5071 5046 5037>,
			<7488 5990 5329 5079 5067 5048>,
			<7551 6029 5340 5094 5079 5070>,
			<7526 6028 5342 5101 5069 5066>,
			<7613 6084 5341 5077 5041 5030>,
			<7716 6170 5359 5075 5045 5036>,
			<7880 6314 5412 5083 5051 5044>,
			<8433 6511 5491 5103 5061 5040>,
			<9651 6820 5616 5144 5109 5083>,
			<9651 6820 5616 5144 5109 5083>,
			<9651 6820 5616 5144 5109 5083>;
	};

};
